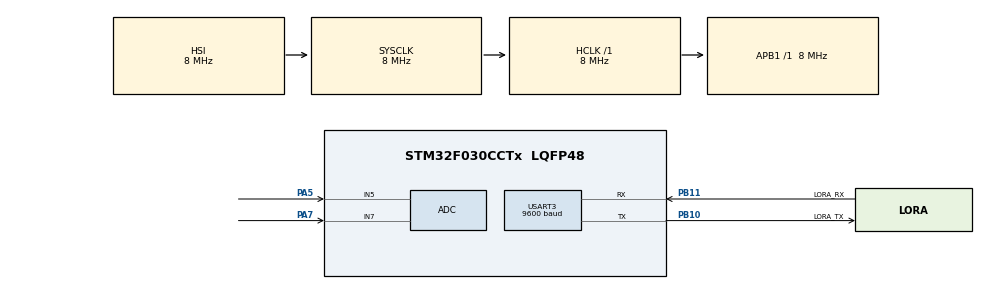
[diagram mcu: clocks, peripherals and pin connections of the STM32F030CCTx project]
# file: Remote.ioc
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ADC.SamplingTime=ADC_SAMPLETIME_239CYCLES_5
Mcu.Family=STM32F0
Mcu.Name=STM32F030CCTx
Mcu.Package=LQFP48
PA13.Mode=Serial_Wire
PA13.Signal=SYS_SWDIO
PA14.Mode=Serial_Wire
PA14.Signal=SYS_SWCLK
PA5.Mode=IN5
PA5.Signal=ADC_IN5
PA7.Mode=IN7
PA7.Signal=ADC_IN7
PB10.GPIO_Label=LORA_TX
PB10.Mode=Asynchronous
PB10.Signal=USART3_TX
PB11.GPIO_Label=LORA_RX
PB11.Mode=Asynchronous
PB11.Signal=USART3_RX
ProjectManager.HeapSize=0x200
ProjectManager.StackSize=0x400
ProjectManager.TargetToolchain=STM32CubeIDE
RCC.AHBFreq_Value=8000000
RCC.APB1Freq_Value=8000000
RCC.APB1TimFreq_Value=8000000
RCC.HCLKFreq_Value=8000000
RCC.SYSCLKFreq_VALUE=8000000
USART3.BaudRate=9600
USART3.VirtualMode-Asynchronous=VM_ASYNC
board=custom

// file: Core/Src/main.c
/* USER CODE BEGIN Header */
/**
  ******************************************************************************
  * @file           : main.c
  * @brief          : Main program body
  ******************************************************************************
  * @attention
  *
  * Copyright (c) 2024 STMicroelectronics.
  * All rights reserved.
  *
  * This software is licensed under terms that can be found in the LICENSE file
  * in the root directory of this software component.
  * If no LICENSE file comes with this software, it is provided AS-IS.
  *
  ******************************************************************************
  */
/* USER CODE END Header */
#include "main.h"

/* USER CODE BEGIN Includes */
#include "remote.h"
/* USER CODE END Includes */

ADC_HandleTypeDef hadc;

UART_HandleTypeDef huart3;

void SystemClock_Config(void);
static void MX_GPIO_Init(void);
static void MX_ADC_Init(void);
static void MX_USART3_UART_Init(void);

int main(void)
{

  /* MCU Configuration--------------------------------------------------------*/

  /* Reset of all peripherals, Initializes the Flash interface and the Systick. */
  HAL_Init();

  /* Configure the system clock */
  SystemClock_Config();

  /* Initialize all configured peripherals */
  MX_GPIO_Init();
  MX_ADC_Init();
  MX_USART3_UART_Init();
  /* USER CODE BEGIN 2 */
  remote_init();
  /* USER CODE END 2 */

  /* Infinite loop */
  while (1)
  {

	  remote_process();

  }
}

void SystemClock_Config(void)
{
  RCC_OscInitTypeDef RCC_OscInitStruct = {0};
  RCC_ClkInitTypeDef RCC_ClkInitStruct = {0};

  /** Initializes the RCC Oscillators according to the specified parameters
  * in the RCC_OscInitTypeDef structure.
  */
  RCC_OscInitStruct.OscillatorType = RCC_OSCILLATORTYPE_HSI|RCC_OSCILLATORTYPE_HSI14;
  RCC_OscInitStruct.HSIState = RCC_HSI_ON;
  RCC_OscInitStruct.HSI14State = RCC_HSI14_ON;
  RCC_OscInitStruct.HSICalibrationValue = RCC_HSICALIBRATION_DEFAULT;
  RCC_OscInitStruct.HSI14CalibrationValue = 16;
  RCC_OscInitStruct.PLL.PLLState = RCC_PLL_NONE;
  if (HAL_RCC_OscConfig(&RCC_OscInitStruct) != HAL_OK)
  {
    Error_Handler();
  }

  /** Initializes the CPU, AHB and APB buses clocks
  */
  RCC_ClkInitStruct.ClockType = RCC_CLOCKTYPE_HCLK|RCC_CLOCKTYPE_SYSCLK
                              |RCC_CLOCKTYPE_PCLK1;
  RCC_ClkInitStruct.SYSCLKSource = RCC_SYSCLKSOURCE_HSI;
  RCC_ClkInitStruct.AHBCLKDivider = RCC_SYSCLK_DIV1;
  RCC_ClkInitStruct.APB1CLKDivider = RCC_HCLK_DIV1;

  if (HAL_RCC_ClockConfig(&RCC_ClkInitStruct, FLASH_LATENCY_0) != HAL_OK)
  {
    Error_Handler();
  }
}

static void MX_ADC_Init(void)
{

  ADC_ChannelConfTypeDef sConfig = {0};

  /** Configure the global features of the ADC (Clock, Resolution, Data Alignment and number of conversion)
  */
  hadc.Instance = ADC1;
  hadc.Init.ClockPrescaler = ADC_CLOCK_ASYNC_DIV1;
  hadc.Init.Resolution = ADC_RESOLUTION_12B;
  hadc.Init.DataAlign = ADC_DATAALIGN_RIGHT;
  hadc.Init.ScanConvMode = ADC_SCAN_DIRECTION_FORWARD;
  hadc.Init.EOCSelection = ADC_EOC_SINGLE_CONV;
  hadc.Init.LowPowerAutoWait = DISABLE;
  hadc.Init.LowPowerAutoPowerOff = DISABLE;
  hadc.Init.ContinuousConvMode = DISABLE;
  hadc.Init.DiscontinuousConvMode = DISABLE;
  hadc.Init.ExternalTrigConv = ADC_SOFTWARE_START;
  hadc.Init.ExternalTrigConvEdge = ADC_EXTERNALTRIGCONVEDGE_NONE;
  hadc.Init.DMAContinuousRequests = DISABLE;
  hadc.Init.Overrun = ADC_OVR_DATA_PRESERVED;
  if (HAL_ADC_Init(&hadc) != HAL_OK)
  {
    Error_Handler();
  }

  /** Configure for the selected ADC regular channel to be converted.
  */
  sConfig.Channel = ADC_CHANNEL_5;
  sConfig.Rank = ADC_RANK_CHANNEL_NUMBER;
  sConfig.SamplingTime = ADC_SAMPLETIME_239CYCLES_5;
  if (HAL_ADC_ConfigChannel(&hadc, &sConfig) != HAL_OK)
  {
    Error_Handler();
  }

  /** Configure for the selected ADC regular channel to be converted.
  */
  sConfig.Channel = ADC_CHANNEL_7;
  if (HAL_ADC_ConfigChannel(&hadc, &sConfig) != HAL_OK)
  {
    Error_Handler();
  }

}

static void MX_USART3_UART_Init(void)
{

  huart3.Instance = USART3;
  huart3.Init.BaudRate = 9600;
  huart3.Init.WordLength = UART_WORDLENGTH_8B;
  huart3.Init.StopBits = UART_STOPBITS_1;
  huart3.Init.Parity = UART_PARITY_NONE;
  huart3.Init.Mode = UART_MODE_TX_RX;
  huart3.Init.HwFlowCtl = UART_HWCONTROL_NONE;
  huart3.Init.OverSampling = UART_OVERSAMPLING_16;
  huart3.Init.OneBitSampling = UART_ONE_BIT_SAMPLE_DISABLE;
  huart3.AdvancedInit.AdvFeatureInit = UART_ADVFEATURE_NO_INIT;
  if (HAL_UART_Init(&huart3) != HAL_OK)
  {
    Error_Handler();
  }

}

static void MX_GPIO_Init(void)
{

  /* GPIO Ports Clock Enable */
  __HAL_RCC_GPIOA_CLK_ENABLE();
  __HAL_RCC_GPIOB_CLK_ENABLE();

}

void Error_Handler(void)
{
  __disable_irq();
  while (1)
  {
  }
}
